# PIC32MX270F512H register map
Vendor: Microchip
Registers are 32-bit, read-write, reset 0x0 unless marked. A register's access mark holds for its fields unless they carry their own. Addresses are absolute, and some are shared; only a register's first bit layout is shown; [hi:lo] are bit positions; {n}, {i} and the like mark numbered series.

## TRAN_Ports
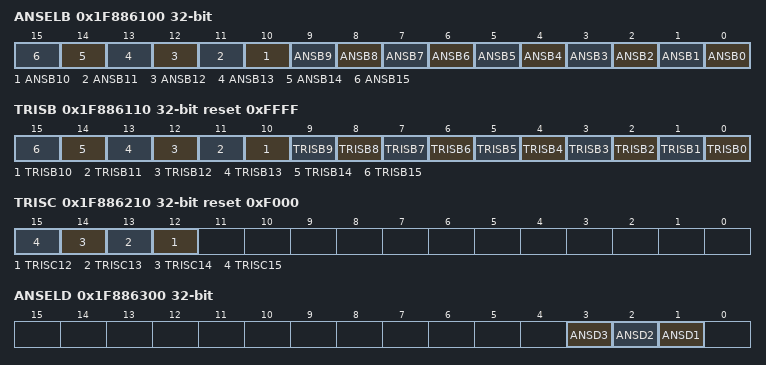
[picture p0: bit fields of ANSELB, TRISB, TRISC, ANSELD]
0x1F886100 ANSELB reset not defined — (power-on value ----------------xxxxxxxxxxxxxxxx)
  [n] ANSB{n} (n=0..15)
0x1F886110 TRISB reset 0xFFFF
  [n] TRISB{n} (n=0..15)
0x1F886200 ANSELC access not given reset not defined
0x1F886210 TRISC reset 0xF000
  [n] TRISC{n} (n=12..15)
0x1F886300 ANSELD reset not defined — (power-on value ----------------------------xxx-)
  [3] ANSD3, [2] ANSD2, [1] ANSD1
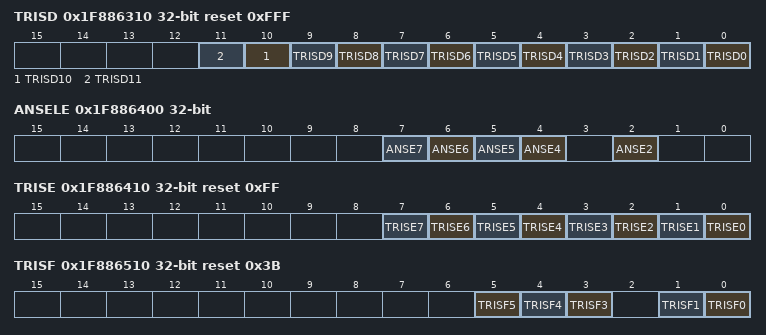
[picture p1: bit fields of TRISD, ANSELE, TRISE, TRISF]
0x1F886310 TRISD reset 0xFFF
  [n] TRISD{n} (n=0..11)
0x1F886400 ANSELE reset not defined — (power-on value ------------------------xxxx-x--)
  [n] ANSE{n} (n=4..7), [2] ANSE2
0x1F886410 TRISE reset 0xFF
  [n] TRISE{n} (n=0..7)
0x1F886500 ANSELF access not given reset not defined
0x1F886510 TRISF reset 0x3B
  [5] TRISF5, [4] TRISF4, [3] TRISF3, [1] TRISF1, [0] TRISF0
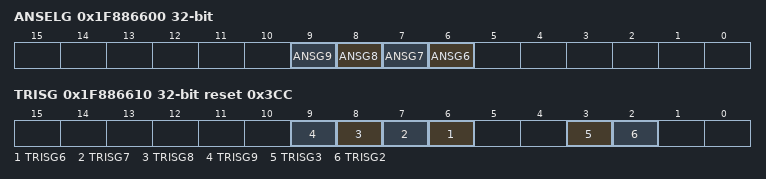
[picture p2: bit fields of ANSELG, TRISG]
0x1F886600 ANSELG reset not defined — (power-on value ----------------------xxxx------)
  [n] ANSG{n} (n=6..9)
0x1F886610 TRISG reset 0x3CC
  [n] TRISG{n} (n=6..9), [3] TRISG3, [2] TRISG2

## PORTB
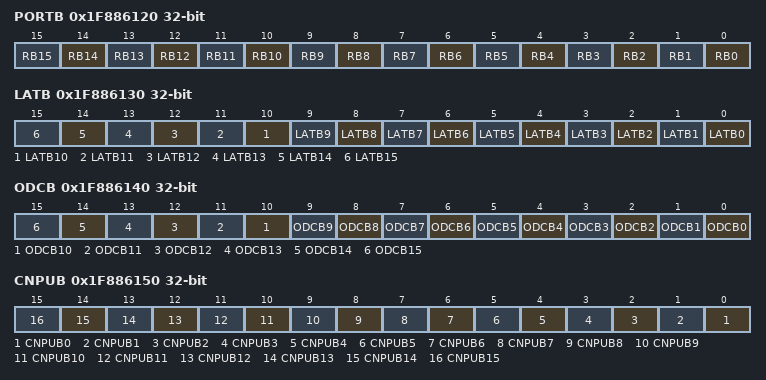
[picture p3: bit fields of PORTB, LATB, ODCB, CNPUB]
0x1F886120 PORTB reset not defined — (power-on value ----------------xxxxxxxxxxxxxxxx)
  [n] RB{n} (n=0..15)
0x1F886130 LATB reset not defined — (power-on value ----------------xxxxxxxxxxxxxxxx)
  [n] LATB{n} (n=0..15)
0x1F886140 ODCB
  [n] ODCB{n} (n=0..15)
0x1F886150 CNPUB reset not defined — (power-on value ----------------xxxxxxxxxxxxxxxx)
  [n] CNPUB{n} (n=0..15)
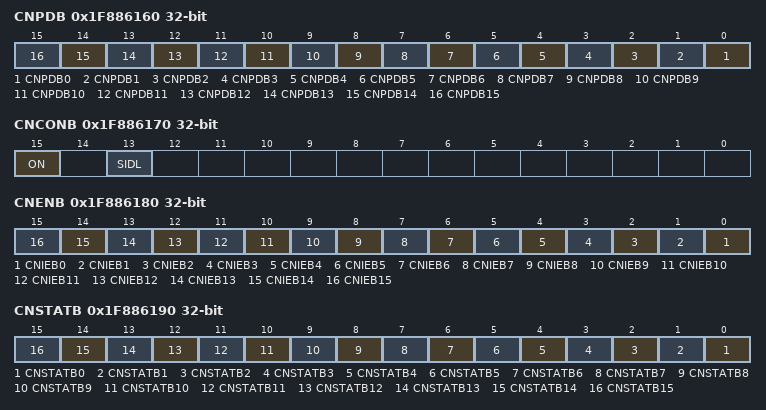
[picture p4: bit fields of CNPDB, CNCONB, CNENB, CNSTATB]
0x1F886160 CNPDB reset not defined — (power-on value ----------------xxxxxxxxxxxxxxxx)
  [n] CNPDB{n} (n=0..15)
0x1F886170 CNCONB
  [15] ON, [13] SIDL
0x1F886180 CNENB reset not defined — (power-on value 0000000000------xxxxxxxxxxxxxxxx)
  [n] CNIEB{n} (n=0..15)
0x1F886190 CNSTATB reset not defined — (power-on value ----------------xxxxxxxxxxxxxxxx)
  [n] CNSTATB{n} (n=0..15)

## PORTC
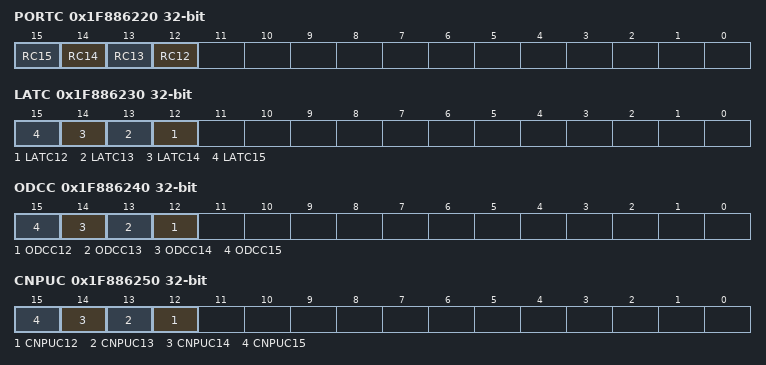
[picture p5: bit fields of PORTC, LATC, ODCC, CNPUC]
0x1F886220 PORTC reset not defined — (power-on value ----------------xxxx------------)
  [n] RC{n} (n=12..15)
0x1F886230 LATC reset not defined — (power-on value ----------------xxxx------------)
  [n] LATC{n} (n=12..15)
0x1F886240 ODCC
  [n] ODCC{n} (n=12..15)
0x1F886250 CNPUC reset not defined — (power-on value ----------------xxxx------------)
  [n] CNPUC{n} (n=12..15)
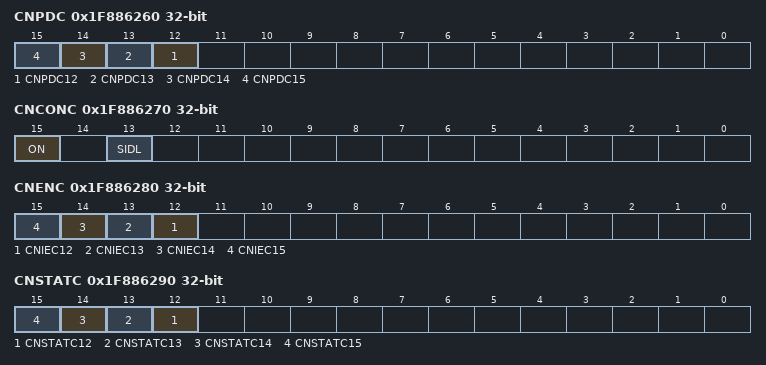
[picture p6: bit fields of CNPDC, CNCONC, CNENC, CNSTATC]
0x1F886260 CNPDC reset not defined — (power-on value ----------------xxxx------------)
  [n] CNPDC{n} (n=12..15)
0x1F886270 CNCONC
  [15] ON, [13] SIDL
0x1F886280 CNENC reset not defined — (power-on value 0000000000------xxxx------------)
  [n] CNIEC{n} (n=12..15)
0x1F886290 CNSTATC reset not defined — (power-on value ----------------xxxx------------)
  [n] CNSTATC{n} (n=12..15)

## PORTD
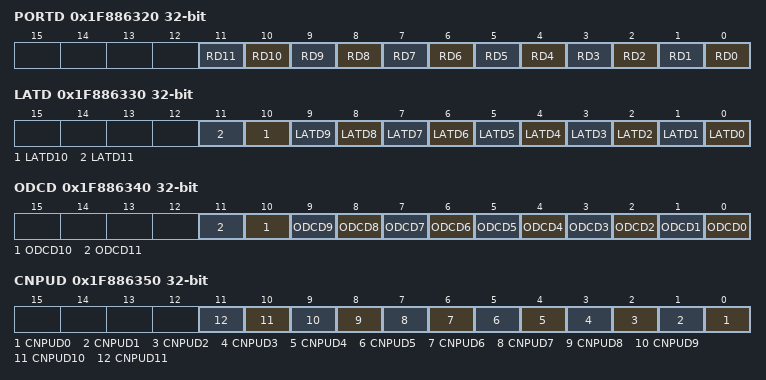
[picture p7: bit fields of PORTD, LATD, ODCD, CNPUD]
0x1F886320 PORTD reset not defined — (power-on value --------------------xxxxxxxxxxxx)
  [n] RD{n} (n=0..11)
0x1F886330 LATD reset not defined — (power-on value --------------------xxxxxxxxxxxx)
  [n] LATD{n} (n=0..11)
0x1F886340 ODCD
  [n] ODCD{n} (n=0..11)
0x1F886350 CNPUD reset not defined — (power-on value --------------------xxxxxxxxxxxx)
  [n] CNPUD{n} (n=0..11)
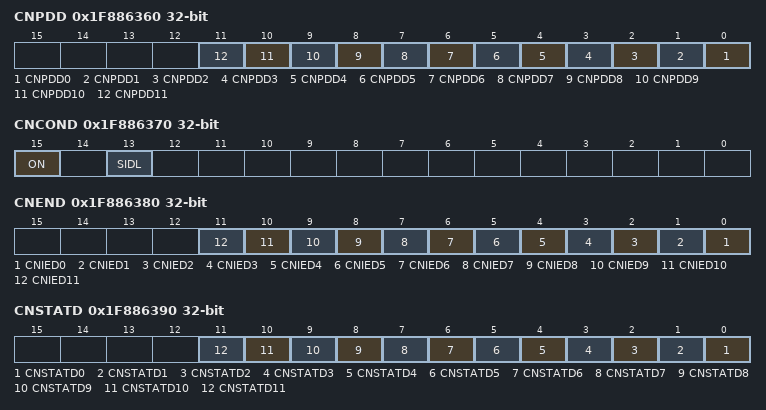
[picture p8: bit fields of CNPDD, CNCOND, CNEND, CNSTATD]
0x1F886360 CNPDD reset not defined — (power-on value --------------------xxxxxxxxxxxx)
  [n] CNPDD{n} (n=0..11)
0x1F886370 CNCOND
  [15] ON, [13] SIDL
0x1F886380 CNEND reset not defined — (power-on value 0000000000----------xxxxxxxxxxxx)
  [n] CNIED{n} (n=0..11)
0x1F886390 CNSTATD reset not defined — (power-on value --------------------xxxxxxxxxxxx)
  [n] CNSTATD{n} (n=0..11)

## PORTE
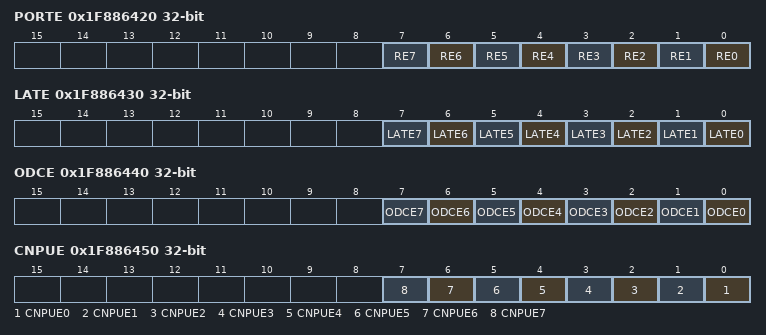
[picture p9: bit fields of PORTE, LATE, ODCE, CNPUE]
0x1F886420 PORTE reset not defined — (power-on value ------------------------xxxxxxxx)
  [n] RE{n} (n=0..7)
0x1F886430 LATE reset not defined — (power-on value ------------------------xxxxxxxx)
  [n] LATE{n} (n=0..7)
0x1F886440 ODCE
  [n] ODCE{n} (n=0..7)
0x1F886450 CNPUE reset not defined — (power-on value ------------------------xxxxxxxx)
  [n] CNPUE{n} (n=0..7)
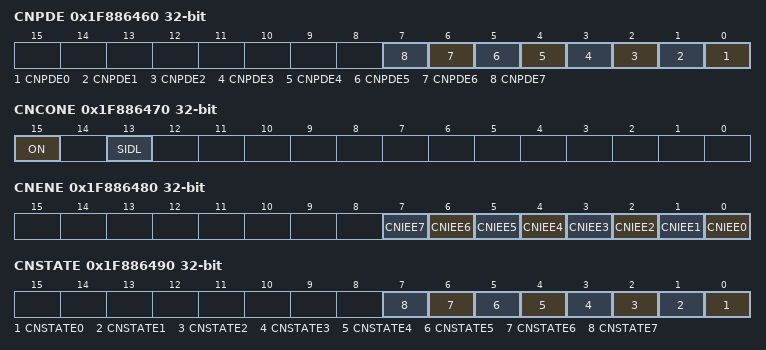
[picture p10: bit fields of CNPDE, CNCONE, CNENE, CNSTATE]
0x1F886460 CNPDE reset not defined — (power-on value ------------------------xxxxxxxx)
  [n] CNPDE{n} (n=0..7)
0x1F886470 CNCONE
  [15] ON, [13] SIDL
0x1F886480 CNENE reset not defined — (power-on value 0000000000--------------xxxxxxxx)
  [n] CNIEE{n} (n=0..7)
0x1F886490 CNSTATE reset not defined — (power-on value ------------------------xxxxxxxx)
  [n] CNSTATE{n} (n=0..7)

## PORTF
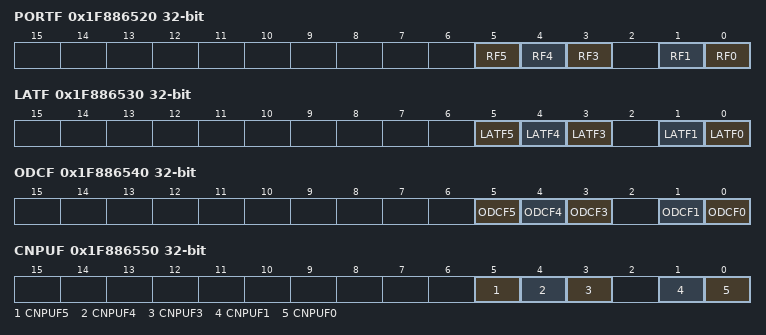
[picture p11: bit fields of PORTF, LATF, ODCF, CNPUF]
0x1F886520 PORTF reset not defined — (power-on value --------------------------xxx-xx)
  [5] RF5, [4] RF4, [3] RF3, [1] RF1, [0] RF0
0x1F886530 LATF reset not defined — (power-on value --------------------------xxx-xx)
  [5] LATF5, [4] LATF4, [3] LATF3, [1] LATF1, [0] LATF0
0x1F886540 ODCF
  [5] ODCF5, [4] ODCF4, [3] ODCF3, [1] ODCF1, [0] ODCF0
0x1F886550 CNPUF reset not defined — (power-on value --------------------------xxx-xx)
  [5] CNPUF5, [4] CNPUF4, [3] CNPUF3, [1] CNPUF1, [0] CNPUF0
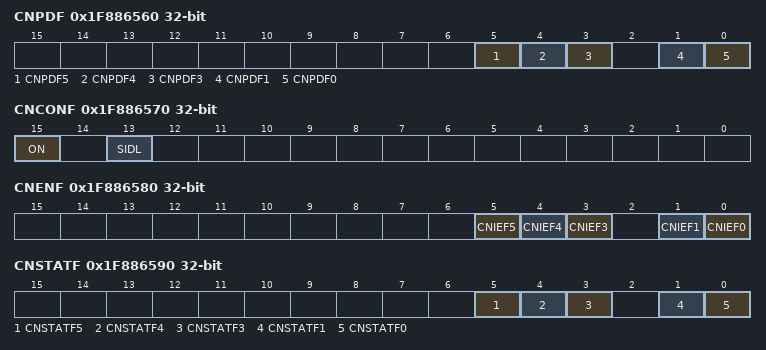
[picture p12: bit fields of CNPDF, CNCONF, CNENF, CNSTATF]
0x1F886560 CNPDF reset not defined — (power-on value --------------------------xxx-xx)
  [5] CNPDF5, [4] CNPDF4, [3] CNPDF3, [1] CNPDF1, [0] CNPDF0
0x1F886570 CNCONF
  [15] ON, [13] SIDL
0x1F886580 CNENF reset not defined — (power-on value 0000000000----------------xxx-xx)
  [5] CNIEF5, [4] CNIEF4, [3] CNIEF3, [1] CNIEF1, [0] CNIEF0
0x1F886590 CNSTATF reset not defined — (power-on value --------------------------xxx-xx)
  [5] CNSTATF5, [4] CNSTATF4, [3] CNSTATF3, [1] CNSTATF1, [0] CNSTATF0

## PORTG
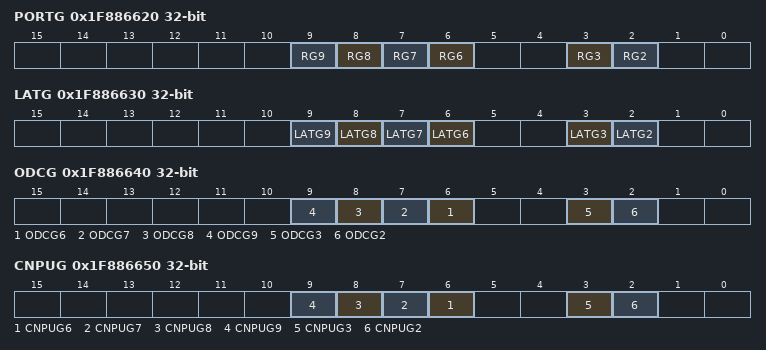
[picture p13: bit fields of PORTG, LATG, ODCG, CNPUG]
0x1F886620 PORTG reset not defined — (power-on value ----------------------xxxx--xx--)
  [n] RG{n} (n=6..9), [3] RG3, [2] RG2
0x1F886630 LATG reset not defined — (power-on value ----------------------xxxx--xx--)
  [n] LATG{n} (n=6..9), [3] LATG3, [2] LATG2
0x1F886640 ODCG
  [n] ODCG{n} (n=6..9), [3] ODCG3, [2] ODCG2
0x1F886650 CNPUG reset not defined — (power-on value ----------------------xxxx--xx--)
  [n] CNPUG{n} (n=6..9), [3] CNPUG3, [2] CNPUG2
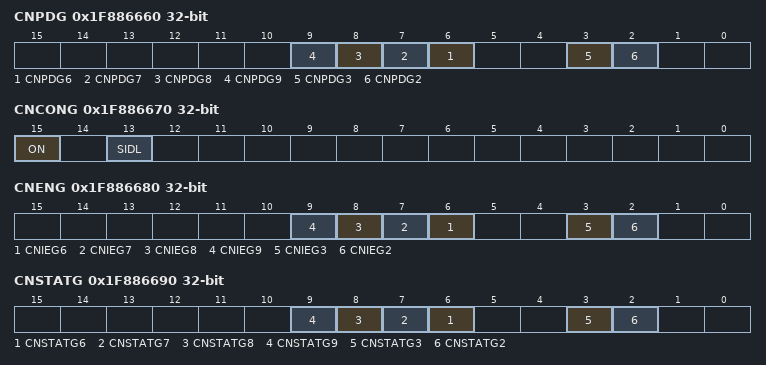
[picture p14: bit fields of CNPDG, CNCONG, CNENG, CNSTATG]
0x1F886660 CNPDG reset not defined — (power-on value ----------------------xxxx--xx--)
  [n] CNPDG{n} (n=6..9), [3] CNPDG3, [2] CNPDG2
0x1F886670 CNCONG
  [15] ON, [13] SIDL
0x1F886680 CNENG reset not defined — (power-on value 0000000000------------xxxx--xx--)
  [n] CNIEG{n} (n=6..9), [3] CNIEG3, [2] CNIEG2
0x1F886690 CNSTATG reset not defined — (power-on value ----------------------xxxx--xx--)
  [n] CNSTATG{n} (n=6..9), [3] CNSTATG3, [2] CNSTATG2
